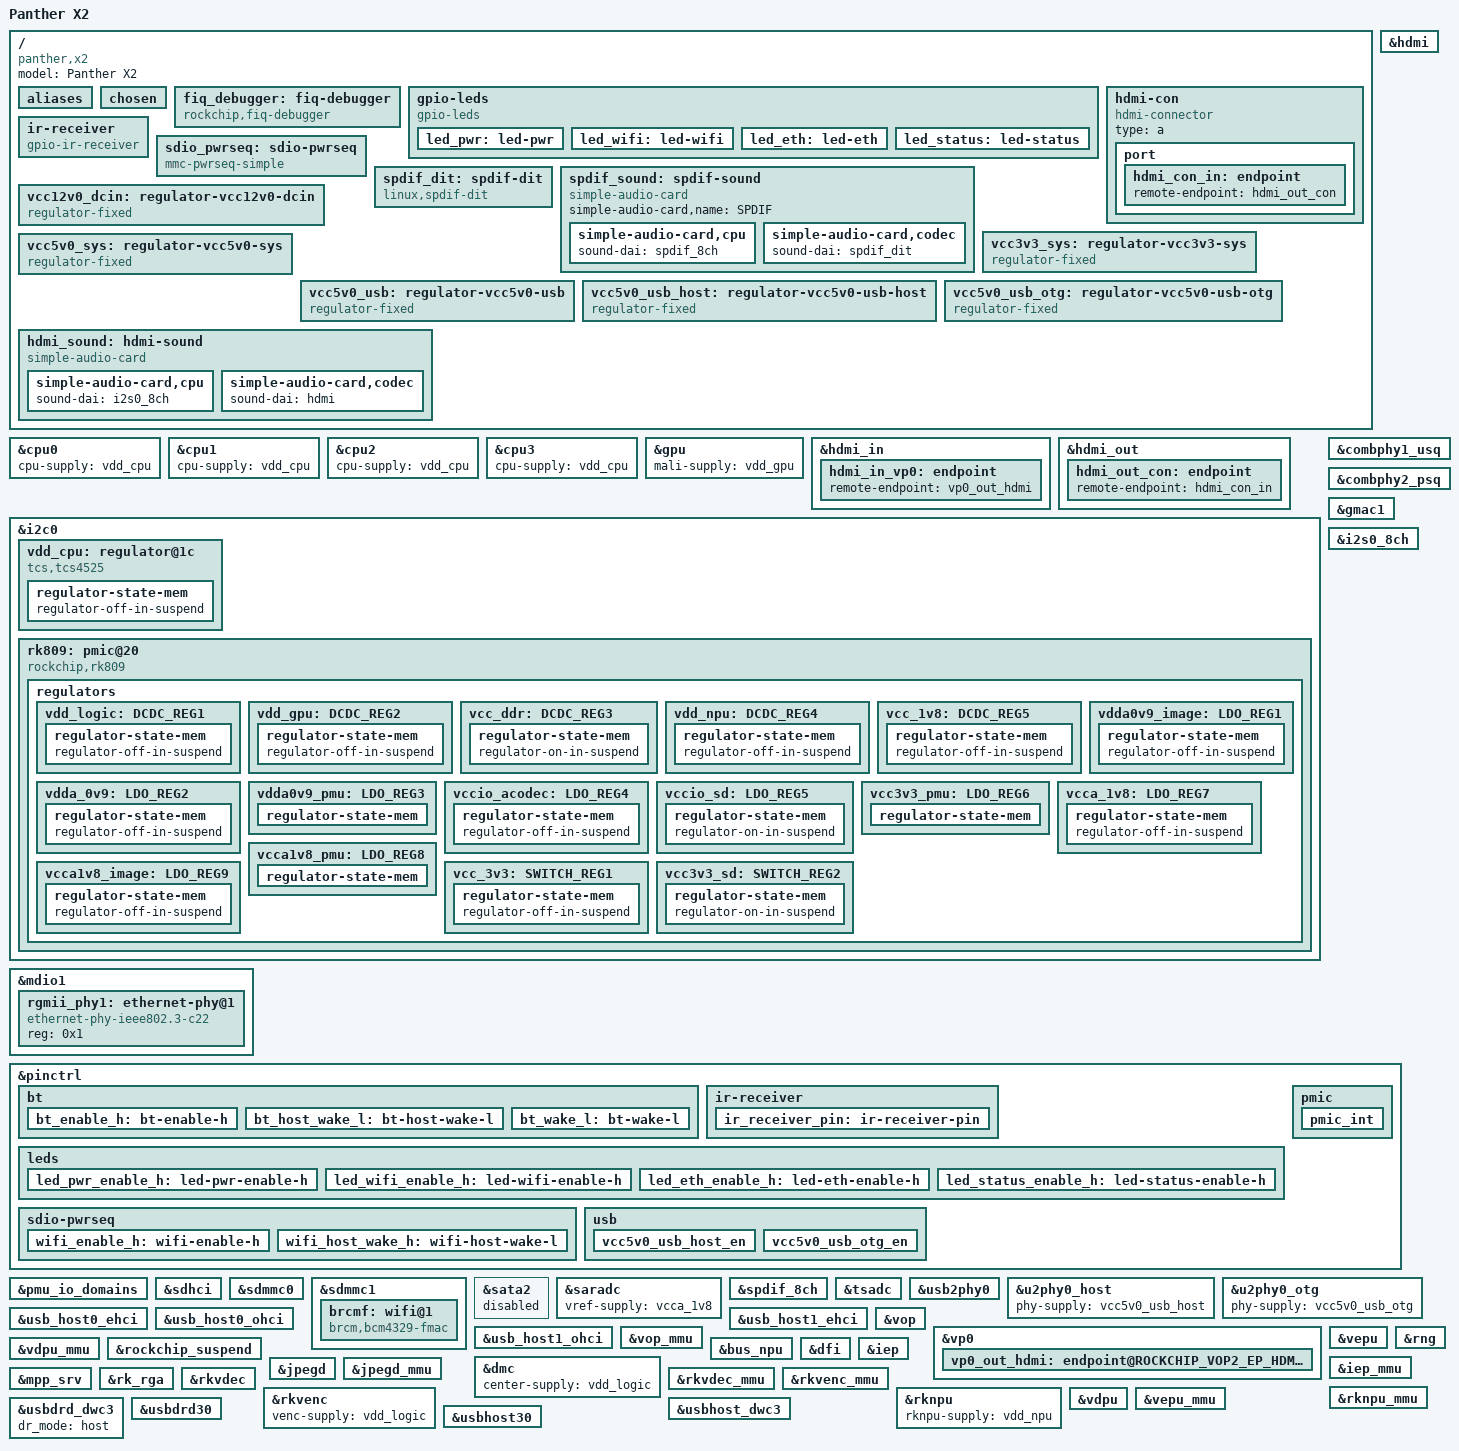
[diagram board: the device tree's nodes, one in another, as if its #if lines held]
/dts-v1/;

#include <dt-bindings/gpio/gpio.h>
#include <dt-bindings/interrupt-controller/irq.h>
#include <dt-bindings/pinctrl/rockchip.h>
#ifdef DTS_NO_LEGACY
#include <dt-bindings/soc/rockchip,vop2.h>
#else
#include <dt-bindings/display/rockchip_vop.h>
#endif
#include "rk3566.dtsi"

/ {
	model = "Panther X2";
	compatible = "panther,x2", "rockchip,rk3566";

	aliases {
		ethernet0 = &gmac1;
		mmc0 = &sdhci;
		mmc1 = &sdmmc0;
		mmc2 = &sdmmc1;
	};

	chosen: chosen {
		bootargs = "earlycon=uart8250,mmio32,0xfe660000 console=ttyFIQ0 root=PARTUUID=614e0000-0000 rw rootwait";
	};

	fiq_debugger: fiq-debugger {
		compatible = "rockchip,fiq-debugger";
		rockchip,serial-id = <2>;
		rockchip,wake-irq = <0>;
		/* If enable uart uses irq instead of fiq */
		rockchip,irq-mode-enable = <1>;
		rockchip,baudrate = <1500000>;  /* Only 115200 and 1500000 */
		interrupts = <GIC_SPI 252 IRQ_TYPE_LEVEL_LOW>;
		pinctrl-names = "default";
		pinctrl-0 = <&uart2m0_xfer>;
		status = "okay";
	};

    gpio-leds {
        compatible = "gpio-leds";
        led_pwr: led-pwr {
            label = "led-pwr";
            default-state = "on";
            gpios = <&gpio0 RK_PD4 GPIO_ACTIVE_HIGH>;
            pinctrl-names = "default";
            pinctrl-0 = <&led_pwr_enable_h>;
            retain-state-suspended;
            status = "okay";
        };
        
        led_wifi: led-wifi {
            label = "led-wifi";
            default-state = "off";
            gpios = <&gpio0 RK_PD6 GPIO_ACTIVE_HIGH>;
            pinctrl-names = "default";
            pinctrl-0 = <&led_wifi_enable_h>;
            retain-state-suspended;
            status = "okay";
        };
        
        led_eth: led-eth {
            label = "led-eth";
            default-state = "off";
            gpios = <&gpio0 RK_PD5 GPIO_ACTIVE_HIGH>;
            pinctrl-names = "default";
            pinctrl-0 = <&led_eth_enable_h>;
            retain-state-suspended;
            status = "okay";
        };
        
        led_status: led-status {
            label = "led-status";
            default-state = "on";
            gpios = <&gpio0 RK_PD3 GPIO_ACTIVE_HIGH>;
            linux,default-trigger = "heartbeat";
            pinctrl-names = "default";
            pinctrl-0 = <&led_status_enable_h>;
            retain-state-suspended;
            status = "okay";
        };
    };

#ifdef DTS_NO_LEGACY
	hdmi-con {
		compatible = "hdmi-connector";
		type = "a";

		port {
			hdmi_con_in: endpoint {
				remote-endpoint = <&hdmi_out_con>;
			};
		};
	};
#endif

	ir-receiver {
		compatible = "gpio-ir-receiver";
		gpios = <&gpio0 RK_PC2 GPIO_ACTIVE_LOW>;
		pinctrl-names = "default";
		pinctrl-0 = <&ir_receiver_pin>;
	};

	sdio_pwrseq: sdio-pwrseq {
		status = "okay";
		compatible = "mmc-pwrseq-simple";
		clocks = <&rk809 1>;
		clock-names = "ext_clock";
		pinctrl-names = "default";
		pinctrl-0 = <&wifi_enable_h>;
		reset-gpios = <&gpio2 RK_PB1 GPIO_ACTIVE_LOW>;
		post-power-on-delay-ms = <200>;
	};

	spdif_dit: spdif-dit {
		compatible = "linux,spdif-dit";
		#sound-dai-cells = <0>;
	};

	spdif_sound: spdif-sound {
		compatible = "simple-audio-card";
		simple-audio-card,name = "SPDIF";

		simple-audio-card,cpu {
			sound-dai = <&spdif_8ch>;
		};

		simple-audio-card,codec {
			sound-dai = <&spdif_dit>;
		};
	};

	vcc12v0_dcin: regulator-vcc12v0-dcin {
		compatible = "regulator-fixed";
		regulator-name = "vcc12v0_dcin";
		regulator-always-on;
		regulator-boot-on;
		regulator-min-microvolt = <12000000>;
		regulator-max-microvolt = <12000000>;
	};

	vcc3v3_sys: regulator-vcc3v3-sys {
		compatible = "regulator-fixed";
		regulator-name = "vcc3v3_sys";
		regulator-always-on;
		regulator-boot-on;
		regulator-min-microvolt = <3300000>;
		regulator-max-microvolt = <3300000>;
		vin-supply = <&vcc12v0_dcin>;
	};

	vcc5v0_sys: regulator-vcc5v0-sys {
		compatible = "regulator-fixed";
		regulator-name = "vcc5v0_sys";
		regulator-always-on;
		regulator-boot-on;
		regulator-min-microvolt = <5000000>;
		regulator-max-microvolt = <5000000>;
		vin-supply = <&vcc12v0_dcin>;
	};

	vcc5v0_usb: regulator-vcc5v0-usb {
		compatible = "regulator-fixed";
		regulator-boot-on;
		regulator-always-on;
		regulator-name = "vcc5v0_usb";
		regulator-min-microvolt = <5000000>;
		regulator-max-microvolt = <5000000>;
		vin-supply = <&vcc12v0_dcin>;
	};

	vcc5v0_usb_host: regulator-vcc5v0-usb-host {
		compatible = "regulator-fixed";
		enable-active-high;
		gpio = <&gpio0 RK_PA6 GPIO_ACTIVE_HIGH>;
		pinctrl-names = "default";
		pinctrl-0 = <&vcc5v0_usb_host_en>;
		regulator-name = "vcc5v0_usb_host";
		regulator-min-microvolt = <5000000>;
		regulator-max-microvolt = <5000000>;
		vin-supply = <&vcc5v0_usb>;
	};

	vcc5v0_usb_otg: regulator-vcc5v0-usb-otg {
		compatible = "regulator-fixed";
		enable-active-high;
		gpio = <&gpio0 RK_PA5 GPIO_ACTIVE_HIGH>;
		pinctrl-names = "default";
		pinctrl-0 = <&vcc5v0_usb_otg_en>;
		regulator-name = "vcc5v0_usb_otg";
		regulator-min-microvolt = <5000000>;
		regulator-max-microvolt = <5000000>;
		vin-supply = <&vcc5v0_usb>;
	};

	hdmi_sound: hdmi-sound {
		compatible = "simple-audio-card";
		simple-audio-card,format = "i2s";
		simple-audio-card,mclk-fs = <128>;
		simple-audio-card,name = "rockchip,hdmi";
		status = "disabled";

		simple-audio-card,cpu {
				sound-dai = <&i2s0_8ch>;
		};
		simple-audio-card,codec {
				sound-dai = <&hdmi>;
		};
	};
};

&cpu0 {
	cpu-supply = <&vdd_cpu>;
};

&cpu1 {
	cpu-supply = <&vdd_cpu>;
};

&cpu2 {
	cpu-supply = <&vdd_cpu>;
};

&cpu3 {
	cpu-supply = <&vdd_cpu>;
};

&gpu {
	mali-supply = <&vdd_gpu>;
	status = "okay";
};

&hdmi {
	assigned-clocks = <&cru CLK_HDMI_CEC>;
	assigned-clock-rates = <32768>;
	avdd-0v9-supply = <&vdda_0v9>;
	avdd-1v8-supply = <&vcca_1v8>;
	status = "okay";
};

#ifdef DTS_NO_LEGACY
&hdmi_in {
	hdmi_in_vp0: endpoint {
		remote-endpoint = <&vp0_out_hdmi>;
	};
};

&hdmi_out {
	hdmi_out_con: endpoint {
		remote-endpoint = <&hdmi_con_in>;
	};
};
#else
&hdmi_in_vp0 {
	status = "okay";
};

&hdmi_in_vp1 {
	status = "disabled";
};
#endif



&hdmi_sound {
	status = "okay";
};

&i2c0 {
	status = "okay";

	vdd_cpu: regulator@1c {
		compatible = "tcs,tcs4525";
		reg = <0x1c>;
		fcs,suspend-voltage-selector = <1>;
		regulator-name = "vdd_cpu";
		regulator-min-microvolt = <800000>;
		regulator-max-microvolt = <1150000>;
		regulator-ramp-delay = <2300>;
		regulator-always-on;
		regulator-boot-on;
		vin-supply = <&vcc5v0_sys>;

		regulator-state-mem {
			regulator-off-in-suspend;
		};
	};

	rk809: pmic@20 {
		compatible = "rockchip,rk809";
		reg = <0x20>;
		interrupt-parent = <&gpio0>;
		interrupts = <RK_PA3 IRQ_TYPE_LEVEL_LOW>;
		//assigned-clocks = <&cru I2S1_MCLKOUT_TX>;
		//assigned-clock-parents = <&cru CLK_I2S1_8CH_TX>;
		//clock-names = "mclk";
		//clocks = <&cru I2S1_MCLKOUT_TX>;
		clock-output-names = "rk808-clkout1", "rk808-clkout2";

		pinctrl-names = "default";
		pinctrl-0 = <&pmic_int>;
		rockchip,system-power-controller;
		wakeup-source;
		#clock-cells = <1>;

		vcc1-supply = <&vcc3v3_sys>;
		vcc2-supply = <&vcc3v3_sys>;
		vcc3-supply = <&vcc3v3_sys>;
		vcc4-supply = <&vcc3v3_sys>;
		vcc5-supply = <&vcc3v3_sys>;
		vcc6-supply = <&vcc3v3_sys>;
		vcc7-supply = <&vcc3v3_sys>;
		vcc8-supply = <&vcc3v3_sys>;
		vcc9-supply = <&vcc3v3_sys>;

		regulators {
			vdd_logic: DCDC_REG1 {
				regulator-name = "vdd_logic";
				regulator-always-on;
				regulator-boot-on;
				regulator-init-microvolt = <900000>;
				regulator-min-microvolt  = <500000>;
				regulator-max-microvolt  = <1350000>;
				regulator-initial-mode   = <0x2>;
				regulator-ramp-delay     = <6001>;
				regulator-state-mem {
					regulator-off-in-suspend;
				};
			};

			vdd_gpu: DCDC_REG2 {
				regulator-name = "vdd_gpu";
				regulator-always-on;
				regulator-boot-on;
				regulator-init-microvolt = <900000>;
				regulator-min-microvolt  = <500000>;
				regulator-max-microvolt  = <1350000>;
				regulator-initial-mode   = <0x2>;
				regulator-ramp-delay     = <6001>;
				regulator-state-mem {
					regulator-off-in-suspend;
				};
			};

			vcc_ddr: DCDC_REG3 {
				regulator-name = "vcc_ddr";
				regulator-always-on;
				regulator-boot-on;
				regulator-initial-mode = <0x2>;
				regulator-state-mem {
					regulator-on-in-suspend;
				};
			};

			vdd_npu: DCDC_REG4 {
				regulator-name = "vdd_npu";
				regulator-boot-on;
				regulator-always-on;
				regulator-init-microvolt = <900000>;
				regulator-min-microvolt  = <500000>;
				regulator-max-microvolt  = <1350000>;
				regulator-initial-mode   = <0x2>;
				regulator-ramp-delay     = <6001>;
				regulator-state-mem {
					regulator-off-in-suspend;
				};
			};

			vcc_1v8: DCDC_REG5 {
				regulator-name = "vcc_1v8";
				regulator-always-on;
				regulator-boot-on;
				regulator-min-microvolt = <1800000>;
				regulator-max-microvolt = <1800000>;

				regulator-state-mem {
					regulator-off-in-suspend;
				};
			};

			vdda0v9_image: LDO_REG1 {
				regulator-name = "vdda0v9_image";
				regulator-always-on;
				regulator-boot-on;
				regulator-min-microvolt = <900000>;
				regulator-max-microvolt = <900000>;

				regulator-state-mem {
					regulator-off-in-suspend;
				};
			};

			vdda_0v9: LDO_REG2 {
				regulator-name = "vdda_0v9";
				regulator-always-on;
				regulator-boot-on;
				regulator-min-microvolt = <900000>;
				regulator-max-microvolt = <900000>;

				regulator-state-mem {
					regulator-off-in-suspend;
				};
			};

			vdda0v9_pmu: LDO_REG3 {
				regulator-name = "vdda0v9_pmu";
				regulator-always-on;
				regulator-boot-on;
				regulator-min-microvolt = <900000>;
				regulator-max-microvolt = <900000>;
				regulator-state-mem {
					regulator-on-in-suspend;
					regulator-suspend-microvolt = <900000>;
				};
			};

			vccio_acodec: LDO_REG4 {
				regulator-name = "vccio_acodec";
				regulator-always-on;
				regulator-boot-on;
				regulator-min-microvolt = <3000000>;
				regulator-max-microvolt = <3000000>;

				regulator-state-mem {
					regulator-off-in-suspend;
				};
			};

			vccio_sd: LDO_REG5 {
				regulator-name = "vccio_sd";
				regulator-always-on;
				regulator-boot-on;
				regulator-min-microvolt = <1800000>;
				regulator-max-microvolt = <3300000>;

				regulator-state-mem {
					regulator-on-in-suspend;
				};
			};

			vcc3v3_pmu: LDO_REG6 {
				regulator-name = "vcc3v3_pmu";
				regulator-always-on;
				regulator-boot-on;
				regulator-min-microvolt = <3300000>;
				regulator-max-microvolt = <3300000>;

				regulator-state-mem {
					regulator-on-in-suspend;
					regulator-suspend-microvolt = <3300000>;
				};
			};

			vcca_1v8: LDO_REG7 {
				regulator-name = "vcca_1v8";
				regulator-always-on;
				regulator-boot-on;
				regulator-min-microvolt = <1800000>;
				regulator-max-microvolt = <1800000>;

				regulator-state-mem {
					regulator-off-in-suspend;
				};
			};

			vcca1v8_pmu: LDO_REG8 {
				regulator-name = "vcca1v8_pmu";
				regulator-always-on;
				regulator-boot-on;
				regulator-min-microvolt = <1800000>;
				regulator-max-microvolt = <1800000>;

				regulator-state-mem {
					regulator-on-in-suspend;
					regulator-suspend-microvolt = <1800000>;
				};
			};

			vcca1v8_image: LDO_REG9 {
				regulator-name = "vcca1v8_image";
				regulator-always-on;
				regulator-boot-on;
				regulator-min-microvolt = <1800000>;
				regulator-max-microvolt = <1800000>;

				regulator-state-mem {
					regulator-off-in-suspend;
				};
			};

			vcc_3v3: SWITCH_REG1 {
				regulator-boot-on;
				regulator-always-on;
				regulator-name = "vcc_3v3";
				regulator-state-mem {
					regulator-off-in-suspend;
				};
			};

			vcc3v3_sd: SWITCH_REG2 {
				regulator-boot-on;
				regulator-always-on;
				regulator-name = "vcc3v3_sd";
				regulator-state-mem {
					regulator-on-in-suspend;
				};
			};
		};
	};
};

&combphy1_usq {
	status = "okay";
};

&combphy2_psq {
	status = "okay";
};

&gmac1 {
	snps,reset-gpio = <&gpio3 RK_PA1 GPIO_ACTIVE_HIGH>;
	snps,reset-active-low;
	/* Reset time is 20ms, 100ms for rtl8211f */
	snps,reset-delays-us = <0 20000 100000>;

	phy-mode = "rgmii";
	clock_in_out = "output";

	assigned-clocks = <&cru SCLK_GMAC1_RX_TX>, <&cru SCLK_GMAC1>;
	assigned-clock-parents = <&cru SCLK_GMAC1_RGMII_SPEED>, <&cru CLK_MAC1_2TOP>;
	assigned-clock-rates = <0>, <125000000>;

	pinctrl-names = "default";
	pinctrl-0 = <&gmac1m0_miim
			&gmac1m0_tx_bus2_level3
			&gmac1m0_rx_bus2
			&gmac1m0_rgmii_clk_level2
			&gmac1m0_rgmii_bus_level3>;

	tx_delay = <0x41>;
	rx_delay = <0x2e>;

	phy-handle = <&rgmii_phy1>;
	status = "okay";
};

&mdio1 {
	rgmii_phy1: ethernet-phy@1 {
		compatible = "ethernet-phy-ieee802.3-c22";
		reg = <0x1>;
		status = "okay";
	};
};

&i2s0_8ch {
	status = "okay";
};

&pinctrl {
	bt {
		bt_enable_h: bt-enable-h {
			rockchip,pins = <2 RK_PB7 RK_FUNC_GPIO &pcfg_pull_none>;
		};

		bt_host_wake_l: bt-host-wake-l {
			rockchip,pins = <2 RK_PC0 RK_FUNC_GPIO &pcfg_pull_down>;
		};

		bt_wake_l: bt-wake-l {
			rockchip,pins = <2 RK_PC1 RK_FUNC_GPIO &pcfg_pull_none>;
		};
	};
	ir-receiver {
		ir_receiver_pin: ir-receiver-pin {
			rockchip,pins = <0 RK_PC2 RK_FUNC_GPIO &pcfg_pull_none>;
		};
	};
    leds {
        led_pwr_enable_h: led-pwr-enable-h {
            rockchip,pins = <0 RK_PD4 RK_FUNC_GPIO &pcfg_pull_none>;
        };
        
        led_wifi_enable_h: led-wifi-enable-h {
            rockchip,pins = <0 RK_PD6 RK_FUNC_GPIO &pcfg_pull_none>;
        };
        
        led_eth_enable_h: led-eth-enable-h {
            rockchip,pins = <0 RK_PD5 RK_FUNC_GPIO &pcfg_pull_none>;
        };

        led_status_enable_h: led-status-enable-h {
            rockchip,pins = <0 RK_PD3 RK_FUNC_GPIO &pcfg_pull_none>;
        };
    };
	pmic {
		pmic_int: pmic_int {
			rockchip,pins =	<0 RK_PA3 RK_FUNC_GPIO &pcfg_pull_up>;
		};
	};

	sdio-pwrseq {
		wifi_enable_h: wifi-enable-h {
			rockchip,pins = <2 RK_PB1 RK_FUNC_GPIO &pcfg_pull_none>;
		};

		wifi_host_wake_h: wifi-host-wake-l {
			rockchip,pins = <2 RK_PB2 RK_FUNC_GPIO &pcfg_pull_none>;
		};
	};

	usb {
		vcc5v0_usb_host_en: vcc5v0_usb_host_en {
			rockchip,pins = <0 RK_PA6 RK_FUNC_GPIO &pcfg_pull_none>;
		};

		vcc5v0_usb_otg_en: vcc5v0_usb_otg_en {
			rockchip,pins = <0 RK_PA5 RK_FUNC_GPIO &pcfg_pull_none>;
		};

	};
};

&pmu_io_domains {
	pmuio1-supply = <&vcc3v3_pmu>;
	pmuio2-supply = <&vcc3v3_pmu>;
	vccio1-supply = <&vccio_acodec>;
	vccio2-supply = <&vcc_1v8>;
	vccio3-supply = <&vccio_sd>;
	vccio4-supply = <&vcc_1v8>;
	vccio5-supply = <&vcc_3v3>;
	vccio6-supply = <&vcc_3v3>;
	vccio7-supply = <&vcc_3v3>;
	status = "okay";
};

&sdhci {
	bus-width = <8>;
	max-frequency = <200000000>;
	no-sdio;
	no-sd;
	mmc-hs200-1_8v;
	supports-emmc;
	non-removable;
	status = "okay";
};

&sdmmc0 {
	bus-width = <4>;
	max-frequency = <150000000>;
	cap-mmc-highspeed;
	cap-sd-highspeed;
	supports-sd;
	disable-wp;
	pinctrl-names = "default";
	pinctrl-0 = <&sdmmc0_bus4 &sdmmc0_clk &sdmmc0_cmd &sdmmc0_det>;
	vmmc-supply = <&vcc3v3_sd>;
	vqmmc-supply = <&vccio_sd>;
	status = "okay";
};

&sdmmc1 {
	#address-cells = <1>;
	#size-cells = <0>;
	bus-width = <4>;
	max-frequency = <150000000>;
	cap-sd-highspeed;
	cap-sdio-irq;
	disable-wp;
	supports-sdio;
	non-removable;
	sd-uhs-sdr104;
	keep-power-in-suspend;
	mmc-pwrseq = <&sdio_pwrseq>;
	pinctrl-names = "default";
	pinctrl-0 = <&sdmmc1_bus4 &sdmmc1_cmd &sdmmc1_clk>;
	status = "okay";

	brcmf: wifi@1 {
		compatible = "brcm,bcm4329-fmac";
		reg = <1>;
		interrupt-parent = <&gpio2>;
		interrupts = <RK_PB2 IRQ_TYPE_LEVEL_HIGH>;
		interrupt-names = "host-wake";
		pinctrl-names = "default";
		pinctrl-0 = <&wifi_host_wake_h>;
	};
};

&sata2 {
	status = "disabled";
};

&saradc {
	vref-supply = <&vcca_1v8>;
	status = "okay";
};

&spdif_8ch {
	status = "okay";
};

&tsadc {
	/* tshut mode 0:CRU 1:GPIO */
	rockchip,hw-tshut-mode = <1>;
	/* tshut polarity 0:LOW 1:HIGH */
	rockchip,hw-tshut-polarity = <0>;
	status = "okay";
};

&usb2phy0 {
	status = "okay";
};

&u2phy0_host {
	phy-supply = <&vcc5v0_usb_host>;
	status = "okay";
};

&u2phy0_otg {
	phy-supply = <&vcc5v0_usb_otg>;
	status = "okay";
};

&usb_host0_ehci {
	status = "okay";
};

&usb_host0_ohci {
	status = "okay";
};

&usb_host1_ehci {
	status = "okay";
};

&usb_host1_ohci {
	status = "okay";
};

&vop {
	assigned-clocks = <&cru DCLK_VOP0>, <&cru DCLK_VOP1>;
	assigned-clock-parents = <&pmucru PLL_HPLL>, <&cru PLL_VPLL>;
	status = "okay";
};

&vop_mmu {
	status = "okay";
};

#ifdef DTS_NO_LEGACY
&vp0 {
	vp0_out_hdmi: endpoint@ROCKCHIP_VOP2_EP_HDMI0 {
		reg = <ROCKCHIP_VOP2_EP_HDMI0>;
		remote-endpoint = <&hdmi_in_vp0>;
	};
};
#endif

&vepu {
	status = "okay";
};

&vdpu_mmu {
	status = "okay";
};

&rng {
	status = "okay";
};

&rockchip_suspend {
	status = "okay";
};

&bus_npu {
	bus-supply = <&vdd_logic>;
	pvtm-supply = <&vdd_cpu>;
	status = "okay";
};

&dfi {
	status = "okay";
};

&dmc {
	center-supply = <&vdd_logic>;
	status = "okay";
};

&iep {
	status = "okay";
};

&iep_mmu {
	status = "okay";
};

&jpegd {
    status = "okay";
};

&jpegd_mmu {
    status = "okay";
};

&mpp_srv {
    status = "okay";
};

&rk_rga {
	status = "okay";
};

&rkvdec {
	status = "okay";
};

&rkvdec_mmu {
	status = "okay";
};

&rkvenc {
	venc-supply = <&vdd_logic>;
	status = "okay";
};

&rkvenc_mmu {
	status = "okay";
};

&rknpu {	
	rknpu-supply = <&vdd_npu>;
	status = "okay";
};

&rknpu_mmu {
	status = "okay";
};

&vdpu {
	status = "okay";
};

&vepu_mmu {
	status = "okay";
};

&usbdrd_dwc3 {
	dr_mode = "host";
	status = "okay";
};

&usbdrd30 {
    status = "okay";
};

&usbhost_dwc3 {
    status = "okay";
};

&usbhost30 {
    status = "okay";
};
